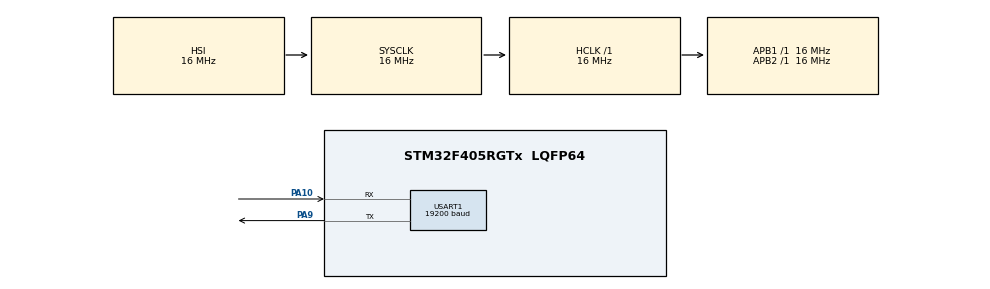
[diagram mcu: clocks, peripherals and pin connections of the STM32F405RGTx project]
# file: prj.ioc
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Mcu.Family=STM32F4
Mcu.Name=STM32F405RGTx
Mcu.Package=LQFP64
NVIC.PriorityGroup=NVIC_PRIORITYGROUP_4
NVIC.TIM4_IRQn=true\:0\:0\:false\:false\:true\:true\:true
NVIC.USART1_IRQn=true\:0\:0\:false\:false\:true\:true\:true
PA10.Mode=LIN
PA10.Signal=USART1_RX
PA13.Mode=Serial_Wire
PA13.Signal=SYS_JTMS-SWDIO
PA14.Mode=Serial_Wire
PA14.Signal=SYS_JTCK-SWCLK
PA9.Mode=LIN
PA9.Signal=USART1_TX
ProjectManager.HeapSize=0x400
ProjectManager.StackSize=0x1000
ProjectManager.TargetToolchain=EWARM V8.32
RCC.AHBFreq_Value=16000000
RCC.APB1Freq_Value=16000000
RCC.APB2Freq_Value=16000000
RCC.CortexFreq_Value=16000000
RCC.HSE_VALUE=25000000
RCC.HSI_VALUE=16000000
RCC.LSE_VALUE=32768
RCC.SYSCLKFreq_VALUE=16000000
RCC.VCOOutputFreq_Value=192000000
TIM4.Prescaler=15999
USART1.BaudRate=19200
USART1.VirtualMode=VM_ASYNC
VP_TIM4_VS_ClockSourceINT.Mode=Internal
board=custom

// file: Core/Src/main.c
/* USER CODE BEGIN Header */
/**
  ******************************************************************************
  * @file           : main.c
  * @brief          : Main program body
  ******************************************************************************
  * @attention
  *
  * <h2><center>&copy; Copyright (c) 2021 STMicroelectronics.
  * All rights reserved.</center></h2>
  *
  * This software component is licensed by ST under BSD 3-Clause license,
  * the "License"; You may not use this file except in compliance with the
  * License. You may obtain a copy of the License at:
  *                        opensource.org/licenses/BSD-3-Clause
  *
  ******************************************************************************
  */
/* USER CODE END Header */
#include "main.h"

TIM_HandleTypeDef htim4;

UART_HandleTypeDef huart1;

void SystemClock_Config(void);
static void MX_GPIO_Init(void);
static void MX_TIM4_Init(void);
static void MX_USART1_UART_Init(void);

/* USER CODE BEGIN 0 */
#include "soft_timer.h"
#include "stm32f4xx_ll_usart.h"

void test_func(void)
{
  uint8_t data_buf[10] = {
      0x01,
      0x03,
      0x89,
      0x1b,
      0x00,
      0x01,
      0xde,
      0x51,
      0x00,
      0x00,
  };
  static uint32_t i = 0;
  if (i < 50)
  {
    LL_USART_RequestBreakSending(USART1);
    LL_USART_TransmitData8(USART1, 0x55);
    while (LL_USART_IsActiveFlag_TXE(USART1) == 0)
      ;
    LL_USART_TransmitData8(USART1, 0x61);
    while (LL_USART_IsActiveFlag_TXE(USART1) == 0)
      ;
  }
  else if (i > 80)
  {
    for (uint8_t j = 0; j < 10; j++)
    {
      LL_USART_TransmitData8(USART1, data_buf[j]);
      while (LL_USART_IsActiveFlag_TXE(USART1) == 0)
        ;
      while(data_buf[j]!=LL_USART_ReceiveData8(USART1));
    }
  }

  i = (i + 1) % 200;
}
/* USER CODE END 0 */

int main(void)
{

  /* MCU Configuration--------------------------------------------------------*/

  /* Reset of all peripherals, Initializes the Flash interface and the Systick. */
  HAL_Init();

  /* Configure the system clock */
  SystemClock_Config();

  /* Initialize all configured peripherals */
  MX_GPIO_Init();
  MX_TIM4_Init();
  MX_USART1_UART_Init();
  /* USER CODE BEGIN 2 */
  soft_timer_create(10, test_func);

  HAL_TIM_Base_Start_IT(&htim4);
  /* USER CODE END 2 */

  /* Infinite loop */
  /* USER CODE BEGIN WHILE */
  while (1)
  {
    soft_timer_run();
    /* USER CODE END WHILE */

  }
}

void SystemClock_Config(void)
{
  RCC_OscInitTypeDef RCC_OscInitStruct = {0};
  RCC_ClkInitTypeDef RCC_ClkInitStruct = {0};

  /** Configure the main internal regulator output voltage
  */
  __HAL_RCC_PWR_CLK_ENABLE();
  __HAL_PWR_VOLTAGESCALING_CONFIG(PWR_REGULATOR_VOLTAGE_SCALE1);
  /** Initializes the RCC Oscillators according to the specified parameters
  * in the RCC_OscInitTypeDef structure.
  */
  RCC_OscInitStruct.OscillatorType = RCC_OSCILLATORTYPE_HSI;
  RCC_OscInitStruct.HSIState = RCC_HSI_ON;
  RCC_OscInitStruct.HSICalibrationValue = RCC_HSICALIBRATION_DEFAULT;
  RCC_OscInitStruct.PLL.PLLState = RCC_PLL_NONE;
  if (HAL_RCC_OscConfig(&RCC_OscInitStruct) != HAL_OK)
  {
    Error_Handler();
  }
  /** Initializes the CPU, AHB and APB buses clocks
  */
  RCC_ClkInitStruct.ClockType = RCC_CLOCKTYPE_HCLK | RCC_CLOCKTYPE_SYSCLK | RCC_CLOCKTYPE_PCLK1 | RCC_CLOCKTYPE_PCLK2;
  RCC_ClkInitStruct.SYSCLKSource = RCC_SYSCLKSOURCE_HSI;
  RCC_ClkInitStruct.AHBCLKDivider = RCC_SYSCLK_DIV1;
  RCC_ClkInitStruct.APB1CLKDivider = RCC_HCLK_DIV1;
  RCC_ClkInitStruct.APB2CLKDivider = RCC_HCLK_DIV1;

  if (HAL_RCC_ClockConfig(&RCC_ClkInitStruct, FLASH_LATENCY_0) != HAL_OK)
  {
    Error_Handler();
  }
}

static void MX_TIM4_Init(void)
{

  TIM_ClockConfigTypeDef sClockSourceConfig = {0};
  TIM_MasterConfigTypeDef sMasterConfig = {0};

  htim4.Instance = TIM4;
  htim4.Init.Prescaler = 0;
  htim4.Init.CounterMode = TIM_COUNTERMODE_UP;
  htim4.Init.Period = 15999;
  htim4.Init.ClockDivision = TIM_CLOCKDIVISION_DIV1;
  htim4.Init.AutoReloadPreload = TIM_AUTORELOAD_PRELOAD_DISABLE;
  if (HAL_TIM_Base_Init(&htim4) != HAL_OK)
  {
    Error_Handler();
  }
  sClockSourceConfig.ClockSource = TIM_CLOCKSOURCE_INTERNAL;
  if (HAL_TIM_ConfigClockSource(&htim4, &sClockSourceConfig) != HAL_OK)
  {
    Error_Handler();
  }
  sMasterConfig.MasterOutputTrigger = TIM_TRGO_RESET;
  sMasterConfig.MasterSlaveMode = TIM_MASTERSLAVEMODE_DISABLE;
  if (HAL_TIMEx_MasterConfigSynchronization(&htim4, &sMasterConfig) != HAL_OK)
  {
    Error_Handler();
  }
}

static void MX_USART1_UART_Init(void)
{

  huart1.Instance = USART1;
  huart1.Init.BaudRate = 19200;
  huart1.Init.WordLength = UART_WORDLENGTH_8B;
  huart1.Init.StopBits = UART_STOPBITS_1;
  huart1.Init.Parity = UART_PARITY_NONE;
  huart1.Init.Mode = UART_MODE_TX_RX;
  huart1.Init.HwFlowCtl = UART_HWCONTROL_NONE;
  huart1.Init.OverSampling = UART_OVERSAMPLING_16;
  if (HAL_LIN_Init(&huart1, UART_LINBREAKDETECTLENGTH_10B) != HAL_OK)
  {
    Error_Handler();
  }
}

static void MX_GPIO_Init(void)
{

  /* GPIO Ports Clock Enable */
  __HAL_RCC_GPIOA_CLK_ENABLE();
}

void Error_Handler(void)
{
  __disable_irq();
  while (1)
  {
  }
}

/************************ (C) COPYRIGHT STMicroelectronics *****END OF FILE****/
